# PT32x060xx register map
File version: 0.1
Registers are 32-bit, read-write, reset 0x0 unless marked. A register's access mark holds for its fields unless they carry their own. Offsets are from the block's base; [hi:lo] are bit positions.

## TIM5 — Advanced timer
Base 0x40014400
Same registers: TIM6 0x40014800
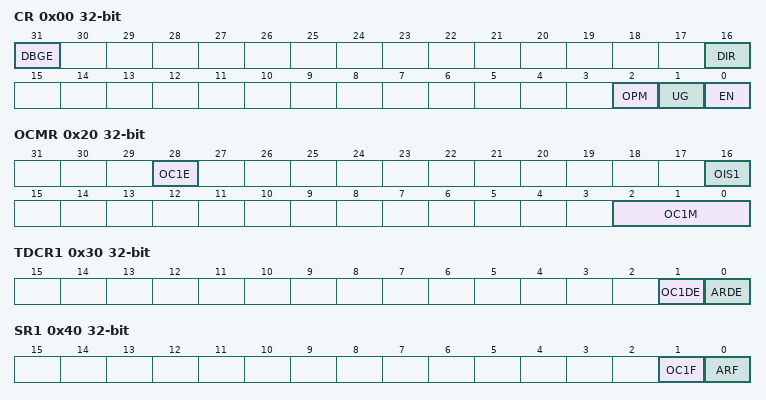
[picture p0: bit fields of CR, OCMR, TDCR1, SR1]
0x00 CR — Control Register
  [31] DBGE — TIM debug
  [16] DIR — Direction
  [2] OPM — One-pulse mode
  [1] UG — Update generation
  [0] EN — TIM enable
0x0C PCR — Polarity Control Register
  [0] CC1P — Capture/Compare 1 output polarity
0x20 OCMR — Output Compare Mode Register
  [28] OC1E — Compare output 1 output enable
  [16] OIS1 — Output Idle state 1
  [2:0] OC1M — output compare 1 mode
0x30 TDCR1 — Trigger DMA Control Register 1
  [1] OC1DE — output compare 1 DMA request enable
  [0] ARDE — auto reload DMA request enable
0x34 TDCR2 — Trigger DMA Control Register 2
  [2] UDE — update DMA request enable
0x40 SR1 — Status Register 1
  [1] OC1F — Output compare 1 flag
  [0] ARF — Auto reload flag
0x44 SR2 — Status Register 2
  [2] UF — update flag
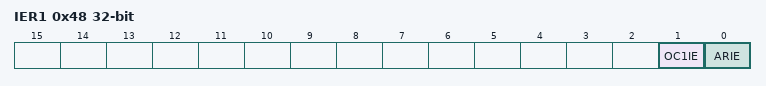
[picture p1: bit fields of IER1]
0x48 IER1 — Interrupt Enable Register 1
  [1] OC1IE — output compare 1 interrupt enable
  [0] ARIE — Auto reload interrupt enable
0x4C IER2 — Interrupt Enable Register 2
  [2] UIE — Update interrupt enable
0x58 PSCR — Prescaler Register
  [15:0] PSC — Prescaler value
0x60 CNTR — Counter Register
  [15:0] CNT — Counter value
0x64 ARR — Auto Reload Register
  [15:0] ARR — Auto reload value
0x68 OCR1 — Output Compare Register 1
  [15:0] OCR — output compare value

## TIM2 — Basic timer
Base 0x40001000
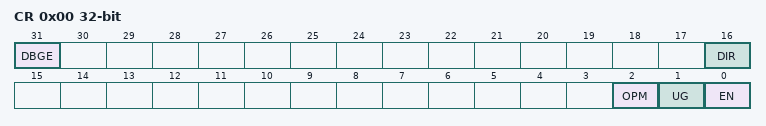
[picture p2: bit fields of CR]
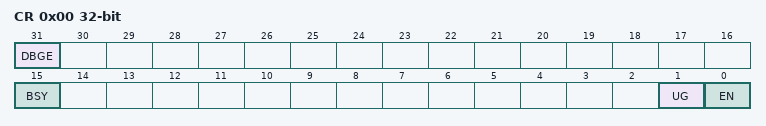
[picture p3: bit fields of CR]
0x00 CR access per field — Control Register
  [31] DBGE rw — TIM debug
  [16] DIR rw — Direction
  [2] OPM rw — One-pulse mode
  [1] UG wo — Counter Update generation
  [0] EN rw — Counter enable
0x40 SR1 — Status Register 1
  [0] ARF — auto reload flag
0x48 IER1 — Interrupt Enable Register 1
  [0] ARIE — Auto reload interrupt enable
0x58 PSCR — Prescaler Register
  [15:0] PSC — Prescaler value
0x60 CNTR — Counter Register
  [15:0] CNT — Counter value
0x64 ARR — Auto Reload Register
  [15:0] ARR — Auto reload value

## TIM4 — Low power timer
Base 0x40001C00
Registers as TIM2; these are added or differ:
0x00 CR access per field — Control Register
  [31] DBGE rw — TIM debug
  [15] BSY ro — TIM busy
  [1] UG rw — Counter Update generation
  [0] EN rw — Counter enable
0x60 CNTR ro — Counter Register
  [15:0] CNT — Counter value

## TIM3 — Basic timer
Base 0x40001400
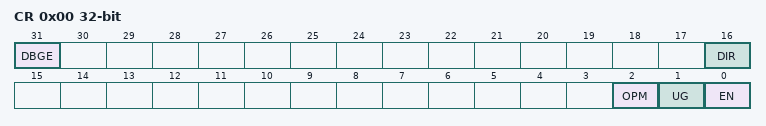
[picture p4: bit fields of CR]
0x00 CR — Control Register
  [31] DBGE — TIM debug
  [16] DIR — Direction
  [2] OPM — One-pulse mode
  [1] UG — Counter Update generation
  [0] EN — Counter enable
0x40 SR1 — Status Register 1
  [0] ARF — auto reload flag
0x48 IER1 — Interrupt Enable Register 1
  [0] ARIE — Auto reload interrupt enable
0x58 PSCR — Prescaler Register
  [31:0] PSC — Prescaler value
0x60 CNTR — Counter Register
  [31:0] CNT — Counter value
0x64 ARR — Auto Reload Register
  [31:0] ARR — Auto reload value

## IWDG — Independent Watchdog
Base 0x40003000
0x00 RLR reset 0xFFFFFFFF — Reload Register
  [31:0] RL — Reload value
0x04 CNTR ro reset 0xFFFFFFFF — Counter Register
  [31:0] CNT — Counter value
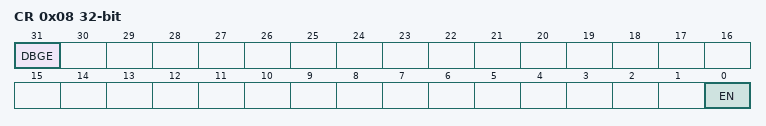
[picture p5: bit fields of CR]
0x08 CR — Control Register
  [31] DBGE — IWDG debug control
  [0] EN — enable
0x0C KR wo — Key Register
  [31:0] KEY — key value
0x10 SR ro — Status Register
  [0] HDF — hungry dog flag
0x33FC LR ro reset 0x1 — Lock Register
  [0] LOCK — lock status

## SPI0 — Serial peripheral interface
Base 0x40013000
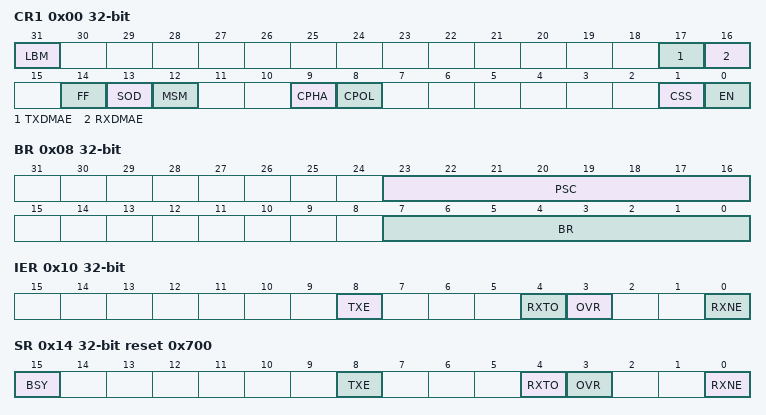
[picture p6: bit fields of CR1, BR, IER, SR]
0x00 CR1 — Control Register 1
  [31] LBM — loopback mode
  [17] TXDMAE — Tx DMA request enable
  [16] RXDMAE — Rx DMA request enable
  [14] FF — Frame format
  [13] SOD — SPI slave output disable
  [12] MSM — master-slave mode
  [9] CPHA — Clock phase
  [8] CPOL — Clock polarity
  [1] CSS — CSS control selection
  [0] EN — SPI Enable
0x04 CR2 reset 0x1 — Control Register 2
  [0] SWCS — Software control CSS
0x08 BR — Baud Rate Prescaler Register
  [23:16] PSC — Prescaler
  [7:0] BR — Baud rate control
0x10 IER — Interrupt Enable Register
  [8] TXE — Transmit/Transmit-FIFO empty interrupt enable
  [4] RXTO — Receive FIFO clear timeout interrupt enable
  [3] OVR — Receive FIFO overflow interrupt enable
  [0] RXNE — Receive FIFO not empty interrupt enable
0x14 SR access per field reset 0x700 — Status Register
  [15] BSY ro — busy flag
  [8] TXE rw — Transmit FIFO empty flag
  [4] RXTO rw — Receive FIFO clear timeout flag
  [3] OVR rw — Receive FIFO overflow flag
  [0] RXNE ro — Receive FIFO not empty flag
0x20 DR — Data Register
  [7:0] DR — SPI data
0x24 DRR wo — Buffer/FIFO Data Reset Register
  [15:0] KEY — FIFO reset key
